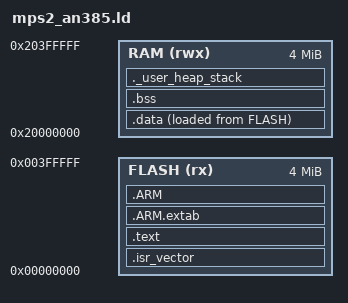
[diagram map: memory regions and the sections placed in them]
/* ARM MPS2-AN385, Cortex-M3.
 * ZBT SRAM at 0x00000000 holds code, SRAM at 0x20000000 holds data.
 * The vector table must sit at address 0: the core fetches the initial stack
 * pointer from 0x00 and the reset vector from 0x04 before any code runs. */
MEMORY
{
  FLASH (rx) : ORIGIN = 0x00000000, LENGTH = 4M
  RAM   (rwx): ORIGIN = 0x20000000, LENGTH = 4M
}

_estack = ORIGIN(RAM) + LENGTH(RAM);
_Min_Heap_Size  = 0x2000;
_Min_Stack_Size = 0x2000;

SECTIONS
{
  .isr_vector : { KEEP(*(.isr_vector)) } > FLASH

  .text : {
    *(.text*) *(.rodata*) *(.glue_7) *(.glue_7t) *(.eh_frame)
    KEEP(*(.init)) KEEP(*(.fini))
    . = ALIGN(4);
    _etext = .;
  } > FLASH

  .ARM.extab : { *(.ARM.extab*) } > FLASH
  .ARM       : { __exidx_start = .; *(.ARM.exidx*) __exidx_end = .; } > FLASH

  _sidata = LOADADDR(.data);
  .data : {
    . = ALIGN(4);
    _sdata = .;
    *(.data*)
    . = ALIGN(4);
    _edata = .;
  } > RAM AT> FLASH

  .bss : {
    . = ALIGN(4);
    _sbss = .;
    __bss_start__ = _sbss;
    *(.bss*) *(COMMON)
    . = ALIGN(4);
    _ebss = .;
    __bss_end__ = _ebss;
  } > RAM

  ._user_heap_stack : {
    . = ALIGN(8);
    PROVIDE ( end = . );
    PROVIDE ( _end = . );
    . = . + _Min_Heap_Size;
    . = . + _Min_Stack_Size;
    . = ALIGN(8);
  } > RAM
}
